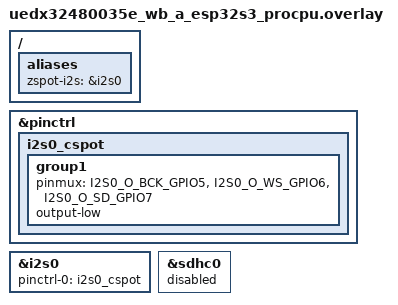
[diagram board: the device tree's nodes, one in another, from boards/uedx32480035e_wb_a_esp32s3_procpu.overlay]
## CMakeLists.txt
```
# Copyright (c) 2026 Muhammad Waleed Badar
# SPDX-License-Identifier: GPL-3.0-only

cmake_minimum_required(VERSION 3.20.0)

# When built outside a west workspace that lists this module, point Zephyr at it.
if(NOT DEFINED ZEPHYR_EXTRA_MODULES)
  set(ZEPHYR_EXTRA_MODULES ${CMAKE_CURRENT_SOURCE_DIR}/../..)
endif()

find_package(Zephyr REQUIRED HINTS $ENV{ZEPHYR_BASE})
project(zspot_player)

target_sources(app PRIVATE src/main.c)
target_sources_ifdef(CONFIG_WIFI_CREDENTIALS_CONNECT_STORED app PRIVATE src/wifi.c)
if(NOT "${CONFIG_ZSPOT_SAMPLE_PCM_FILE}" STREQUAL "")
  target_sources(app PRIVATE src/pcm_file_sink.c)
  target_compile_definitions(app PRIVATE ZSPOT_SAMPLE_HAVE_PCM_FILE=1)
endif()
```

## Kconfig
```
# Copyright (c) 2026 Muhammad Waleed Badar
# SPDX-License-Identifier: GPL-3.0-only

mainmenu "zspot player sample"

config ZSPOT_SAMPLE_CREDENTIALS_JSON
	string "Stored credentials (JSON)"
	default ""
	help
	  Output of zspot_credentials_save_json() from a previous session. When
	  set, the sample skips the zeroconf hand-over.

config ZSPOT_SAMPLE_PCM_FILE
	string "Host file for decoded PCM (native_sim)"
	default ""
	help
	  When set (and the I2S sink is disabled) the decoded audio is appended
	  to this host file as raw 16-bit little-endian stereo PCM at 44.1 kHz.

config ZSPOT_SAMPLE_USERNAME
	string "Spotify username (development only)"
	default ""
	help
	  Together with ZSPOT_SAMPLE_PASSWORD, logs in with a username and
	  password instead of the zeroconf hand-over. Spotify no longer accepts
	  password logins from third-party clients for most accounts, but the
	  attempt still exercises access point resolution, the handshake and
	  the authentication exchange, which is useful on native_sim.

config ZSPOT_SAMPLE_PASSWORD
	string "Spotify password (development only)"
	default ""

source "Kconfig.zephyr"
```

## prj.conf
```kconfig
# Copyright (c) 2026 Muhammad Waleed Badar
# SPDX-License-Identifier: GPL-3.0-only

# --- zspot ---------------------------------------------------------------
CONFIG_ZSPOT=y
CONFIG_ZSPOT_I2S_SINK=y
CONFIG_ZSPOT_LOG_LEVEL_INF=y

# --- C++ runtime for the protocol core -----------------------------------
CONFIG_CPP=y
CONFIG_STD_CPP20=y

# --- Memory ---------------------------------------------------------------
CONFIG_MAIN_STACK_SIZE=8192
# Wi-Fi connect requests run on the system workqueue; the ESP32 driver starts
# up in the caller's context and overflows the 1 KB default.
CONFIG_SYSTEM_WORKQUEUE_STACK_SIZE=4096
CONFIG_HEAP_MEM_POOL_SIZE=24576
CONFIG_DYNAMIC_THREAD_POOL_SIZE=0
CONFIG_DYNAMIC_THREAD_PREFER_ALLOC=y

# --- Networking -----------------------------------------------------------
CONFIG_NETWORKING=y
CONFIG_NET_IPV4=y
CONFIG_NET_IPV6=n
CONFIG_NET_TCP=y
CONFIG_NET_UDP=y
CONFIG_NET_SOCKETS=y
CONFIG_NET_DHCPV4=y
CONFIG_NET_MGMT=y
CONFIG_NET_MGMT_EVENT=y
CONFIG_NET_MGMT_EVENT_INFO=y
CONFIG_NET_CONNECTION_MANAGER=n
CONFIG_NET_HOSTNAME_ENABLE=y
CONFIG_NET_HOSTNAME="zspot"
CONFIG_NET_PKT_RX_COUNT=32
CONFIG_NET_PKT_TX_COUNT=32
CONFIG_NET_BUF_RX_COUNT=64
CONFIG_NET_BUF_TX_COUNT=64
CONFIG_NET_MAX_CONN=10
CONFIG_NET_MAX_CONTEXTS=10
CONFIG_NET_TCP_WORKQ_STACK_SIZE=4096
CONFIG_NET_RX_STACK_SIZE=4096
CONFIG_ZVFS_OPEN_MAX=16
CONFIG_ZVFS_POLL_MAX=16

# DNS: resolver gets the servers from DHCP, static fallback below
CONFIG_DNS_RESOLVER=y
CONFIG_DNS_SERVER_IP_ADDRESSES=y
CONFIG_DNS_SERVER1="8.8.8.8"
CONFIG_DNS_RESOLVER_MAX_SERVERS=3

# mDNS / DNS-SD for discovery by the Spotify app
CONFIG_MDNS_RESPONDER=y
CONFIG_DNS_SD=y
CONFIG_MDNS_RESPONDER_DNS_SD=y

# --- TLS (Spotify endpoints: TLS 1.2, ECDHE-RSA, AES-GCM) -----------------
CONFIG_MBEDTLS=y
CONFIG_MBEDTLS_ENABLE_HEAP=y
CONFIG_MBEDTLS_HEAP_SIZE=98304
CONFIG_MBEDTLS_SSL_IN_CONTENT_LEN=16384
CONFIG_MBEDTLS_SSL_OUT_CONTENT_LEN=4096
CONFIG_MBEDTLS_SSL_PROTO_TLS1_2=y
CONFIG_MBEDTLS_SSL_SERVER_NAME_INDICATION=y
CONFIG_MBEDTLS_KEY_EXCHANGE_ECDHE_RSA_ENABLED=y
CONFIG_MBEDTLS_CIPHERSUITE_TLS_ECDHE_RSA_WITH_AES_128_GCM_SHA256=y
CONFIG_MBEDTLS_CIPHERSUITE_TLS_ECDHE_RSA_WITH_AES_256_GCM_SHA384=y
CONFIG_MBEDTLS_X509_CRT_PARSE_C=y
CONFIG_PSA_CRYPTO=y
CONFIG_PSA_WANT_ALG_SHA_256=y
CONFIG_PSA_WANT_ALG_SHA_384=y
CONFIG_PSA_WANT_ALG_GCM=y
CONFIG_PSA_WANT_ALG_ECDH=y
CONFIG_PSA_WANT_ECC_SECP_R1_256=y
CONFIG_PSA_WANT_ECC_SECP_R1_384=y
CONFIG_PSA_WANT_KEY_TYPE_ECC_KEY_PAIR_GENERATE=y
CONFIG_PSA_WANT_ALG_RSA_PKCS1V15_SIGN=y
CONFIG_PSA_WANT_KEY_TYPE_RSA_PUBLIC_KEY=y
CONFIG_NET_SOCKETS_SOCKOPT_TLS=y
CONFIG_NET_SOCKETS_TLS_MAX_CONTEXTS=4
CONFIG_ENTROPY_GENERATOR=y

# --- Logging --------------------------------------------------------------
CONFIG_LOG=y
CONFIG_LOG_MODE_IMMEDIATE=y
CONFIG_THREAD_NAME=y

# --- Wi-Fi (wifi_credentials library, settings/NVS backend) ----------------
# The Wi-Fi driver is selected per board; boards without Wi-Fi override this
# block (see boards/native_sim_native_64.conf).
CONFIG_WIFI=y
CONFIG_WIFI_CREDENTIALS=y
CONFIG_WIFI_CREDENTIALS_CONNECT_STORED=y
CONFIG_FLASH=y
CONFIG_FLASH_MAP=y
CONFIG_NVS=y
CONFIG_SETTINGS=y
CONFIG_NET_MGMT_EVENT_QUEUE_SIZE=16
CONFIG_NET_MGMT_EVENT_STACK_SIZE=4096

# Shell: "wifi cred add -s <ssid> -k 1 -p <passphrase>", "wifi cred auto_connect"
CONFIG_SHELL=y
CONFIG_SHELL_STACK_SIZE=4096
CONFIG_NET_L2_WIFI_SHELL=y
CONFIG_WIFI_CREDENTIALS_SHELL=y
```

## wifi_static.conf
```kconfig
# Copyright (c) 2026 Muhammad Waleed Badar
# SPDX-License-Identifier: GPL-3.0-only
#
# Bake Wi-Fi credentials into the image instead of adding them on the shell.
# Pass them at build time:
#   -DEXTRA_CONF_FILE=wifi_static.conf
#   -DCONFIG_WIFI_CREDENTIALS_STATIC_SSID=\"<ssid>\"
#   -DCONFIG_WIFI_CREDENTIALS_STATIC_PASSWORD=\"<password>\"

CONFIG_WIFI_CREDENTIALS_STATIC=y
CONFIG_WIFI_CREDENTIALS_BACKEND_SETTINGS=y
```

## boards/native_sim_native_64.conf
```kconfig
# Copyright (c) 2026 Muhammad Waleed Badar
# SPDX-License-Identifier: GPL-3.0-only
#
# native_sim/native/64: Zephyr IP stack over the host TAP interface (zeth). Create it
# on the host first with net-tools: sudo tools/net-tools/net-setup.sh
# Zephyr uses 192.0.2.1, the host side is 192.0.2.2 (gateway and NAT).

CONFIG_NET_L2_ETHERNET=y
CONFIG_ETH_NATIVE_TAP=y
CONFIG_NET_DHCPV4=n
CONFIG_NET_CONFIG_SETTINGS=y
CONFIG_NET_CONFIG_NEED_IPV4=y
CONFIG_NET_CONFIG_MY_IPV4_ADDR="192.0.2.1"
CONFIG_NET_CONFIG_MY_IPV4_NETMASK="255.255.255.0"
CONFIG_NET_CONFIG_MY_IPV4_GW="192.0.2.2"
CONFIG_NET_CONFIG_PEER_IPV4_ADDR="192.0.2.2"

# No Wi-Fi and no flash-backed settings: override the generic Wi-Fi block
CONFIG_WIFI=n
CONFIG_WIFI_CREDENTIALS=n
CONFIG_WIFI_CREDENTIALS_CONNECT_STORED=n
CONFIG_WIFI_CREDENTIALS_SHELL=n
CONFIG_NET_L2_WIFI_SHELL=n
CONFIG_SETTINGS=n
CONFIG_NVS=n
CONFIG_FLASH=n
CONFIG_FLASH_MAP=n

# No I2S: decoded PCM is written to a host file instead
CONFIG_ZSPOT_I2S_SINK=n
CONFIG_ZSPOT_SAMPLE_PCM_FILE="/tmp/zspot.pcm"

# Protocol thread stacks are heap allocated; host RAM is plentiful
CONFIG_HEAP_MEM_POOL_SIZE=262144

CONFIG_ENTROPY_GENERATOR=y
CONFIG_FAKE_ENTROPY_NATIVE_SIM=y

# Console and shell on the terminal instead of a pseudo-tty
CONFIG_UART_NATIVE_PTY_0_ON_STDINOUT=y

# Logs straight to stdout rather than through the shell backend
CONFIG_LOG_BACKEND_NATIVE_POSIX=y
CONFIG_SHELL_LOG_BACKEND=n
```

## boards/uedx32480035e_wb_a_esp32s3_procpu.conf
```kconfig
# Copyright (c) 2026 Muhammad Waleed Badar
# SPDX-License-Identifier: GPL-3.0-only

# 8 MB octal PSRAM (enabled by the board); keep Wi-Fi and net buffers there too
CONFIG_ESP_WIFI_HEAP_SPIRAM=y
CONFIG_ESP32_WIFI_NET_ALLOC_SPIRAM=y

CONFIG_ESP32_WIFI_STATIC_RX_BUFFER_NUM=8
CONFIG_ESP32_WIFI_DYNAMIC_RX_BUFFER_NUM=16
CONFIG_ESP32_WIFI_DYNAMIC_TX_BUFFER_NUM=16

# I2S slab: 6 blocks of 4 KB
CONFIG_CSPOT_I2S_BLOCK_COUNT=6

# libc heap in internal RAM (nanopb and small objects; large buffers use PSRAM)
CONFIG_COMMON_LIBC_MALLOC_ARENA_SIZE=40960

# The Mbed TLS heap is relocated to PSRAM (CSPOT_EXTERNAL_TLS_HEAP_SIZE); keep the static one small
CONFIG_MBEDTLS_HEAP_SIZE=4096
```

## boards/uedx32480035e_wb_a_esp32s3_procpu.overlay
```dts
/*
 * Copyright (c) 2026 Muhammad Waleed Badar
 *
 * SPDX-License-Identifier: GPL-3.0-only
 */

/*
 * VIEWE UEDX32480035E-WB-A (ESP32-S3): external I2S DAC on free GPIOs.
 * BCK = GPIO5, WS (LRCK) = GPIO6, DATA = GPIO7. The remaining GPIOs are used
 * by the display, touch, SD card, USB, RGB LED and buzzer.
 */

/ {
	aliases {
		zspot-i2s = &i2s0;
	};
};

&pinctrl {
	i2s0_cspot: i2s0_cspot {
		group1 {
			pinmux = <I2S0_O_BCK_GPIO5>,
				 <I2S0_O_WS_GPIO6>,
				 <I2S0_O_SD_GPIO7>;
			output-low;
		};
	};
};

&i2s0 {
	status = "okay";
	pinctrl-0 = <&i2s0_cspot>;
	pinctrl-names = "default";
};

/* Not needed by the player; frees the SDMMC pins and driver memory. */
&sdhc0 {
	status = "disabled";
};
```

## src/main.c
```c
/*
 * Copyright (c) 2026 Muhammad Waleed Badar
 *
 * SPDX-License-Identifier: GPL-3.0-only
 */

/*
 * cspot player sample: Spotify Connect receiver with I2S output.
 *
 * Flow: bring the network up, advertise the device, wait for the Spotify app
 * to hand over credentials (or use stored ones), connect, and route decoded
 * PCM to the I2S sink.
 */
#include <errno.h>
#include <stdbool.h>
#include <string.h>

#include <zephyr/device.h>
#include <zephyr/kernel.h>
#include <zephyr/logging/log.h>
#include <zephyr/net/net_event.h>
#include <zephyr/net/net_if.h>
#include <zephyr/net/net_mgmt.h>
#include <zephyr/net/dhcpv4.h>

#include <zspot/zspot.h>

#if defined(CONFIG_WIFI_CREDENTIALS_CONNECT_STORED)
#include "wifi.h"
#endif
#if defined(CONFIG_ZSPOT_I2S_SINK)
#include <zspot/zspot_i2s_sink.h>
#elif defined(ZSPOT_SAMPLE_HAVE_PCM_FILE)
#include "pcm_file_sink.h"
#endif

LOG_MODULE_REGISTER(zspot_player, LOG_LEVEL_INF);

static K_SEM_DEFINE(ipv4_ready, 0, 1);
static struct net_mgmt_event_callback net_cb;

static volatile bool paused;

static void net_event_handler(struct net_mgmt_event_callback *cb, uint64_t event,
			      struct net_if *iface)
{
	ARG_UNUSED(cb);
	ARG_UNUSED(iface);

	if (event == NET_EVENT_IPV4_ADDR_ADD) {
		k_sem_give(&ipv4_ready);
	}
}

static int network_connect(void)
{
	struct net_if *iface = net_if_get_default();

	if (iface == NULL) {
		LOG_ERR("No network interface");
		return -ENODEV;
	}

	net_mgmt_init_event_callback(&net_cb, net_event_handler, NET_EVENT_IPV4_ADDR_ADD);
	net_mgmt_add_event_callback(&net_cb);

#if defined(CONFIG_WIFI_CREDENTIALS_CONNECT_STORED)
	/* Credentials come from the wifi_credentials library (settings or static). */
	int ret = wifi_init();

	if (ret != 0) {
		LOG_ERR("Wi-Fi init failed (%d)", ret);
		return ret;
	}
#endif

#if defined(CONFIG_NET_DHCPV4)
	/* The client waits for the interface to come up before sending DISCOVER. */
	net_dhcpv4_start(iface);
#endif

	/* A static address (CONFIG_NET_CONFIG_SETTINGS) is assigned before main() runs. */
	if (net_if_ipv4_get_global_addr(iface, NET_ADDR_PREFERRED) == NULL) {
		LOG_INF("Waiting for an IPv4 address...");
		k_sem_take(&ipv4_ready, K_FOREVER);
	}
	LOG_INF("Network ready");
	return 0;
}

static void sink_flush(void)
{
#if defined(CONFIG_ZSPOT_I2S_SINK)
	sink_flush();
#endif
}

static void sink_set_volume(uint16_t volume)
{
#if defined(CONFIG_ZSPOT_I2S_SINK)
	zspot_i2s_sink_set_volume(volume);
#else
	ARG_UNUSED(volume);
#endif
}

static int sink_init(void)
{
#if defined(CONFIG_ZSPOT_I2S_SINK)
	return zspot_i2s_sink_init(DEVICE_DT_GET(DT_ALIAS(zspot_i2s)), 44100, 2, 16);
#elif defined(ZSPOT_SAMPLE_HAVE_PCM_FILE)
	return pcm_file_sink_init(CONFIG_ZSPOT_SAMPLE_PCM_FILE);
#else
	return 0;
#endif
}

static size_t sink_write(const uint8_t *pcm, size_t len, void *user_data)
{
#if defined(CONFIG_ZSPOT_I2S_SINK)
	return zspot_i2s_sink_write(pcm, len, user_data);
#elif defined(ZSPOT_SAMPLE_HAVE_PCM_FILE)
	return pcm_file_sink_write(pcm, len, user_data);
#else
	ARG_UNUSED(pcm);
	ARG_UNUSED(user_data);
	return len;
#endif
}

static void on_event(const struct zspot_event *event, void *user_data)
{
	ARG_UNUSED(user_data);

	switch (event->type) {
	case ZSPOT_EVENT_PLAY_PAUSE:
		LOG_INF("%s", event->paused ? "Paused" : "Playing");
		paused = event->paused;
		break;
	case ZSPOT_EVENT_VOLUME:
		LOG_INF("Volume %u", event->volume);
		sink_set_volume(event->volume);
		break;
	case ZSPOT_EVENT_TRACK_INFO:
		LOG_INF("Now playing: %s - %s (%s)", event->track.artist, event->track.name,
			event->track.album);
		break;
	case ZSPOT_EVENT_SEEK:
		LOG_INF("Seek to %u ms", event->position_ms);
		sink_flush();
		break;
	case ZSPOT_EVENT_FLUSH:
	case ZSPOT_EVENT_PLAYBACK_START:
		sink_flush();
		break;
	case ZSPOT_EVENT_DISCONNECT:
		LOG_INF("Playback moved to another device");
		sink_flush();
		break;
	case ZSPOT_EVENT_NEXT:
	case ZSPOT_EVENT_PREV:
		sink_flush();
		break;
	case ZSPOT_EVENT_DEPLETED:
		LOG_INF("Queue finished");
		break;
	}
}

static size_t on_pcm(const uint8_t *pcm, size_t len, void *user_data)
{
	if (paused) {
		return 0; /* player retries shortly */
	}
	return sink_write(pcm, len, user_data);
}

int main(void)
{
	static char credentials[1024];
	const struct zspot_config config = {
		.device_name = CONFIG_ZSPOT_DEVICE_NAME,
		.audio_format = ZSPOT_FORMAT_OGG_VORBIS_160,
		.initial_volume = 0xFFFF, /* unity gain at the sink */
	};
	int ret;

	if (network_connect() != 0) {
		return 0;
	}

	ret = zspot_init(&config);
	if (ret != 0) {
		LOG_ERR("zspot_init failed (%d)", ret);
		return 0;
	}

	ret = sink_init();
	if (ret != 0) {
		LOG_ERR("Audio sink init failed (%d)", ret);
		return 0;
	}

	if (strlen(CONFIG_ZSPOT_SAMPLE_CREDENTIALS_JSON) > 0 &&
	    zspot_credentials_load_json(CONFIG_ZSPOT_SAMPLE_CREDENTIALS_JSON) == 0) {
		LOG_INF("Using stored credentials");
	} else if (strlen(CONFIG_ZSPOT_SAMPLE_USERNAME) > 0 &&
		   zspot_credentials_set_user_pass(CONFIG_ZSPOT_SAMPLE_USERNAME,
						   CONFIG_ZSPOT_SAMPLE_PASSWORD) == 0) {
		LOG_INF("Using username/password credentials");
	} else {
		ret = zspot_zeroconf_start();
		if (ret != 0) {
			LOG_ERR("Zeroconf start failed (%d)", ret);
			return 0;
		}
	}

	while (true) {
		if (!zspot_credentials_available()) {
			LOG_INF("Open Spotify and select \"%s\" in the device list",
				zspot_device_name());
			zspot_zeroconf_wait(-1);
		}

		ret = zspot_connect(on_event, on_pcm, NULL);
		if (ret == 0) {
			break;
		}

		LOG_ERR("zspot_connect failed (%d)", ret);
		if (ret == -EACCES) {
			/* Rejected credentials: go back to waiting for a hand-over. */
			zspot_credentials_clear();
		} else {
			k_sleep(K_SECONDS(5));
		}
	}

	if (zspot_credentials_save_json(credentials, sizeof(credentials)) > 0) {
		LOG_INF("Reusable credentials (store these): %s", credentials);
	}

	/* Everything else happens on the library threads. */
	return 0;
}
```

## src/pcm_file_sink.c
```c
/*
 * Copyright (c) 2026 Muhammad Waleed Badar
 *
 * SPDX-License-Identifier: GPL-3.0-only
 */

/*
 * PCM sink for native_sim: appends the decoded audio to a host file, playable
 * with e.g. "aplay -f S16_LE -r 44100 -c 2 /tmp/zspot.pcm".
 */

#include "pcm_file_sink.h"

#include <errno.h>

#include <nsi_host_trampolines.h>
#include <zephyr/logging/log.h>

LOG_MODULE_DECLARE(zspot_player, LOG_LEVEL_INF);

/* Host open(2) flags (Linux values). */
#define HOST_O_WRONLY 01
#define HOST_O_CREAT  0100
#define HOST_O_TRUNC  01000
#define HOST_MODE_RW  0644

/*
 * nsi_host_open() has no mode argument, which O_CREAT needs; call the host
 * libc directly for this one function. The symbol resolves to the host libc
 * at link time, like the trampolines do.
 */
extern int open(const char *pathname, int flags, ...);

static int pcm_fd = -1;

int pcm_file_sink_init(const char *path)
{
	pcm_fd = open(path, HOST_O_WRONLY | HOST_O_CREAT | HOST_O_TRUNC, HOST_MODE_RW);
	if (pcm_fd < 0) {
		LOG_ERR("Cannot open %s for PCM output", path);
		return -EIO;
	}

	LOG_INF("Writing PCM to %s", path);
	return 0;
}

size_t pcm_file_sink_write(const uint8_t *pcm, size_t len, void *user_data)
{
	ARG_UNUSED(user_data);

	if (pcm_fd < 0) {
		return len;
	}

	long written = nsi_host_write(pcm_fd, pcm, len);

	return written < 0 ? 0 : (size_t)written;
}
```

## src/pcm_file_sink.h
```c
/*
 * Copyright (c) 2026 Muhammad Waleed Badar
 *
 * SPDX-License-Identifier: GPL-3.0-only
 */

#ifndef ZSPOT_SAMPLE_PCM_FILE_SINK_H_
#define ZSPOT_SAMPLE_PCM_FILE_SINK_H_

#include <stddef.h>
#include <stdint.h>

#ifdef __cplusplus
extern "C" {
#endif

/** Opens @p path on the host (native_sim) for raw 16-bit stereo PCM output. */
int pcm_file_sink_init(const char *path);

/** zspot_pcm_cb_t compatible writer. */
size_t pcm_file_sink_write(const uint8_t *pcm, size_t len, void *user_data);

#ifdef __cplusplus
}
#endif

#endif /* ZSPOT_SAMPLE_PCM_FILE_SINK_H_ */
```

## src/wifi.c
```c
/*
 * Copyright (c) 2026 Muhammad Waleed Badar
 *
 * SPDX-License-Identifier: GPL-3.0-only
 */

#include "wifi.h"

#include <zephyr/kernel.h>
#include <zephyr/logging/log.h>
#include <zephyr/net/net_if.h>
#include <zephyr/net/net_mgmt.h>
#include <zephyr/net/wifi_credentials.h>
#include <zephyr/net/wifi_mgmt.h>

LOG_MODULE_DECLARE(zspot_player, LOG_LEVEL_INF);

/* Delay before retrying after a disconnect, a failed attempt or missing credentials */
#define WIFI_RECONNECT_DELAY K_SECONDS(5)

static struct k_work_delayable reconnect_work;
static struct net_mgmt_event_callback wifi_mgmt_cb;

static int wifi_connect(void)
{
	struct net_if *iface = net_if_get_wifi_sta();
	int ret;

	if (iface == NULL) {
		LOG_ERR("No Wi-Fi STA interface");
		return -ENODEV;
	}

	if (wifi_credentials_is_empty()) {
		LOG_WRN("No Wi-Fi credentials stored. Add them with: "
			"wifi cred add -s <ssid> -k 1 -p <passphrase>");
		return -ENOENT;
	}

	ret = net_mgmt(NET_REQUEST_WIFI_CONNECT_STORED, iface, NULL, 0);
	if (ret != 0) {
		LOG_ERR("Connect stored failed: %d", ret);
		return ret;
	}

	LOG_INF("Connecting to WLAN");
	return 0;
}

static void reconnect_handler(struct k_work *work)
{
	ARG_UNUSED(work);

	if (wifi_connect() != 0) {
		(void)k_work_reschedule(&reconnect_work, WIFI_RECONNECT_DELAY);
	}
}

static void wifi_event_handler(struct net_mgmt_event_callback *cb, uint64_t mgmt_event,
			       struct net_if *iface)
{
	const struct wifi_status *status = (const struct wifi_status *)cb->info;

	ARG_UNUSED(iface);

	switch (mgmt_event) {
	case NET_EVENT_WIFI_CONNECT_RESULT:
		if (status->status != 0) {
			LOG_WRN("Wi-Fi connect failed (%d), retrying", status->status);
			(void)k_work_reschedule(&reconnect_work, WIFI_RECONNECT_DELAY);
		} else {
			LOG_INF("Wi-Fi connected");
			(void)k_work_cancel_delayable(&reconnect_work);
		}
		break;
	case NET_EVENT_WIFI_DISCONNECT_RESULT:
		LOG_WRN("Wi-Fi disconnected (reason %d), reconnecting", status->disconn_reason);
		(void)k_work_reschedule(&reconnect_work, WIFI_RECONNECT_DELAY);
		break;
	default:
		break;
	}
}

int wifi_init(void)
{
	int ret;

	k_work_init_delayable(&reconnect_work, reconnect_handler);

	net_mgmt_init_event_callback(&wifi_mgmt_cb, wifi_event_handler,
				     NET_EVENT_WIFI_CONNECT_RESULT | NET_EVENT_WIFI_DISCONNECT_RESULT);
	net_mgmt_add_event_callback(&wifi_mgmt_cb);

	/* First attempt runs from the work queue, like every retry. */
	ret = k_work_schedule(&reconnect_work, K_NO_WAIT);

	return (ret < 0) ? ret : 0;
}
```

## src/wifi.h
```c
/*
 * Copyright (c) 2026 Muhammad Waleed Badar
 *
 * SPDX-License-Identifier: GPL-3.0-only
 */

#ifndef CSPOT_SAMPLE_WIFI_H_
#define CSPOT_SAMPLE_WIFI_H_

#ifdef __cplusplus
extern "C" {
#endif

/**
 * @brief Joins the Wi-Fi network from the credentials stored with the
 *        wifi_credentials library, reconnecting whenever the link drops.
 */
int wifi_init(void);

#ifdef __cplusplus
}
#endif

#endif /* CSPOT_SAMPLE_WIFI_H_ */
```
